# ATSAM4CMS16C_1 register map
Vendor: Atmel; Series: SAM4CM; File version: 0
CPU: CM4 r0p0, selectable endian, no MPU, FPU, 4 interrupt priority bits
Registers are 32-bit, read-write, reset 0x0 unless marked. A register's access mark holds for its fields unless they carry their own. Offsets are from the block's base; [hi:lo] are bit positions; {n}, {i} and the like mark numbered series; 'fields as' and 'values as' point back to an identical list.

## ADC — Analog-to-Digital Converter
Base 0x40038000; register names take the prefix ADC_
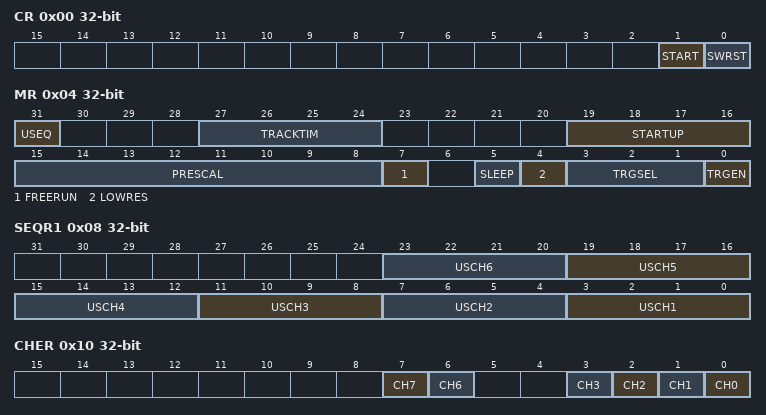
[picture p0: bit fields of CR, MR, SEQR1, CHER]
0x00 CR wo reset not defined — Control Register
  [1] START — Start Conversion
  [0] SWRST — Software Reset
0x04 MR — Mode Register
  [31] USEQ — User Sequence Enable
    0=NUM_ORDER (Normal Mode: The controller converts channels in a simple numeric order depending only on the channel index.); 1=REG_ORDER (User Sequence Mode: The sequence respects what is defined in ADC_SEQR1 and can be used to convert the same channel several times.)
  [27:24] TRACKTIM — Tracking Time
  [19:16] STARTUP — Start Up Time
    0=SUT0 (0 periods of ADC Clock); 1=SUT8 (8 periods of ADC Clock); 2=SUT16 (16 periods of ADC Clock); 3=SUT24 (24 periods of ADC Clock); 4=SUT64 (64 periods of ADC Clock); 5=SUT80 (80 periods of ADC Clock); 6=SUT96 (96 periods of ADC Clock); 7=SUT112 (112 periods of ADC Clock); 8=SUT512 (512 periods of ADC Clock); 9=SUT576 (576 periods of ADC Clock); 10=SUT640 (640 periods of ADC Clock); 11=SUT704 (704 periods of ADC Clock); 12=SUT768 (768 periods of ADC Clock); 13=SUT832 (832 periods of ADC Clock); 14=SUT896 (896 periods of ADC Clock); 15=SUT960 (960 periods of ADC Clock)
  [15:8] PRESCAL — Prescaler Rate Selection
  [7] FREERUN — Free Run Mode
    0=OFF (Normal Mode); 1=ON (Free Run Mode: Never wait for any trigger.)
  [5] SLEEP — Sleep Mode
    0=NORMAL (Normal Mode: The ADC core and reference voltage circuitry are kept ON between conversions); 1=SLEEP (Sleep Mode: The ADC core and reference voltage circuitry are OFF between conversions)
  [4] LOWRES — Resolution
    0=BITS_10 (10-bit resolution. For higher resolution by averaging, refer to Section 8.15 "ADC Extended Mode Register"); 1=BITS_8 (8-bit resolution)
  [3:1] TRGSEL — Trigger Selection
    0=ADC_TRIG0; {v}=ADC_TRIG{v} (Timer Counter Channel {v-1} Output) (v=1..6)
  [0] TRGEN — Trigger Enable
    0=DIS (Hardware triggers are disabled. Starting a conversion is only possible by software.); 1=EN (Hardware trigger selected by TRGSEL field is enabled.)
0x08 SEQR1 — Channel Sequence 1 Register
  [4n-1:4n-4] USCH{n} (n=1..6) — User Sequence Number {n}
0x10 CHER wo reset not defined — Channel Enable Register
  [7] CH7 — Channel 7 Enable
  [6] CH6 — Channel 6 Enable
  [n] CH{n} (n=0..3) — Channel {n} Enable
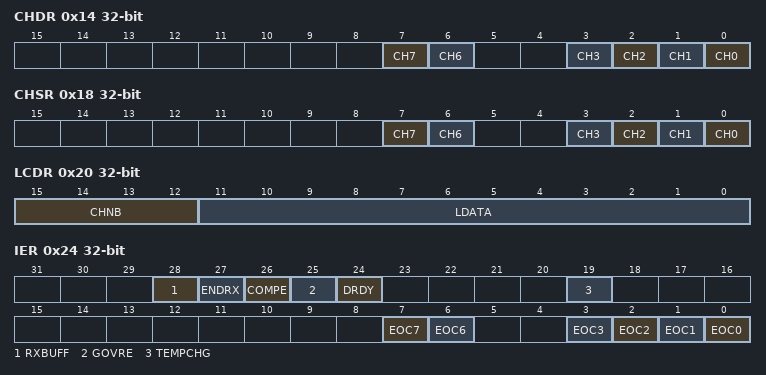
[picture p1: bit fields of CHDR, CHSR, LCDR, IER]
0x14 CHDR wo reset not defined — Channel Disable Register
  [7] CH7 — Channel 7 Disable
  [6] CH6 — Channel 6 Disable
  [n] CH{n} (n=0..3) — Channel {n} Disable
0x18 CHSR ro — Channel Status Register
  [7] CH7 — Channel 7 Status
  [6] CH6 — Channel 6 Status
  [n] CH{n} (n=0..3) — Channel {n} Status
0x20 LCDR ro — Last Converted Data Register
  [15:12] CHNB — Channel Number
  [11:0] LDATA — Last Data Converted
0x24 IER wo reset not defined — Interrupt Enable Register
  [28] RXBUFF — Receive Buffer Full Interrupt Enable
  [27] ENDRX — End of Receive Buffer Interrupt Enable
  [26] COMPE — Comparison Event Interrupt Enable
  [25] GOVRE — General Overrun Error Interrupt Enable
  [24] DRDY — Data Ready Interrupt Enable
  [19] TEMPCHG — Temperature Change Interrupt Enable
  [7] EOC7 — End of Conversion Interrupt Enable 7
  [6] EOC6 — End of Conversion Interrupt Enable 6
  [n] EOC{n} (n=0..3) — End of Conversion Interrupt Enable {n}
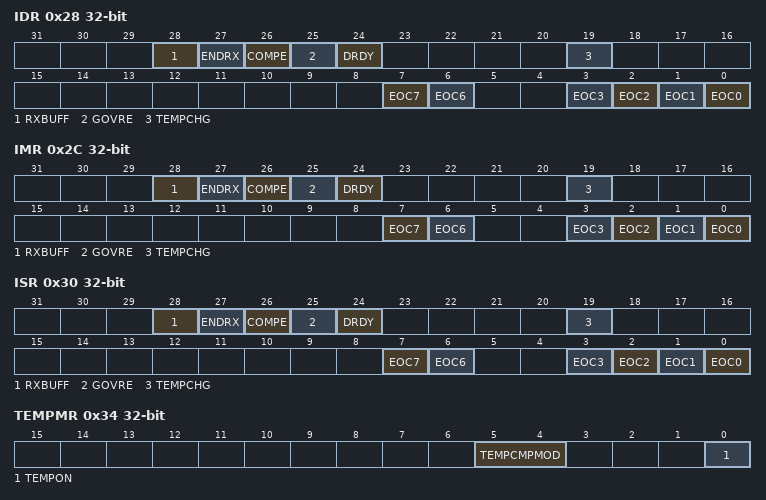
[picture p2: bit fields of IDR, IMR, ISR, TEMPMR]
0x28 IDR wo reset not defined — Interrupt Disable Register
  [28] RXBUFF — Receive Buffer Full Interrupt Disable
  [27] ENDRX — End of Receive Buffer Interrupt Disable
  [26] COMPE — Comparison Event Interrupt Disable
  [25] GOVRE — General Overrun Error Interrupt Disable
  [24] DRDY — Data Ready Interrupt Disable
  [19] TEMPCHG — Temperature Change Interrupt Disable
  [7] EOC7 — End of Conversion Interrupt Disable 7
  [6] EOC6 — End of Conversion Interrupt Disable 6
  [n] EOC{n} (n=0..3) — End of Conversion Interrupt Disable {n}
0x2C IMR ro — Interrupt Mask Register
  [28] RXBUFF — Receive Buffer Full Interrupt Mask
  [27] ENDRX — End of Receive Buffer Interrupt Mask
  [26] COMPE — Comparison Event Interrupt Mask
  [25] GOVRE — General Overrun Error Interrupt Mask
  [24] DRDY — Data Ready Interrupt Mask
  [19] TEMPCHG — Temperature Change Interrupt Mask
  [7] EOC7 — End of Conversion Interrupt Mask 7
  [6] EOC6 — End of Conversion Interrupt Mask 6
  [n] EOC{n} (n=0..3) — End of Conversion Interrupt Mask {n}
0x30 ISR ro — Interrupt Status Register
  [28] RXBUFF — Receive Buffer Full (automatically set/cleared)
  [27] ENDRX — End of Receive Transfer (automatically set/cleared)
  [26] COMPE — Comparison Event (cleared on read)
  [25] GOVRE — General Overrun Error (cleared on read)
  [24] DRDY — Data Ready (automatically set/cleared)
  [19] TEMPCHG — Temperature Change (cleared on read)
  [7] EOC7 — End of Conversion 7 (automatically set/cleared)
  [6] EOC6 — End of Conversion 6 (automatically set/cleared)
  [n] EOC{n} (n=0..3) — End of Conversion {n} (automatically set/cleared)
0x34 TEMPMR — Temperature Sensor Mode Register
  [5:4] TEMPCMPMOD — Temperature Comparison Mode
    0=LOW (Generates an event when the converted data is lower than the low threshold of the window.); 1=HIGH (Generates an event when the converted data is higher than the high threshold of the window.); 2=IN (Generates an event when the converted data is in the comparison window.); 3=OUT (Generates an event when the converted data is out of the comparison window.)
  [0] TEMPON — Temperature Sensor ON
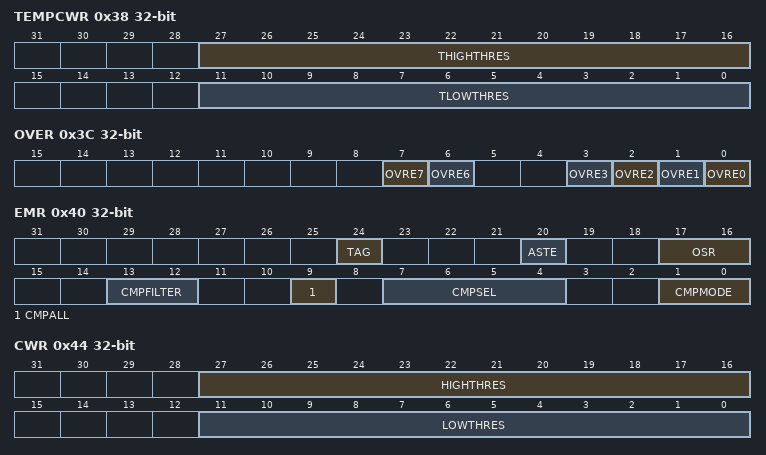
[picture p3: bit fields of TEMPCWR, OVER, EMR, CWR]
0x38 TEMPCWR — Temperature Compare Window Register
  [27:16] THIGHTHRES — Temperature High Threshold
  [11:0] TLOWTHRES — Temperature Low Threshold
0x3C OVER ro — Overrun Status Register
  [7] OVRE7 — Overrun Error 7
  [6] OVRE6 — Overrun Error 6
  [n] OVRE{n} (n=0..3) — Overrun Error {n}
0x40 EMR — Extended Mode Register
  [24] TAG — TAG of the ADC_LDCR register
  [20] ASTE — Averaging on Single Trigger Event
    0=MULTI_TRIG_AVERAGE (The average requests several trigger events.); 1=SINGLE_TRIG_AVERAGE (The average requests only one trigger event.)
  [17:16] OSR — Over Sampling Rate
    0=NO_AVERAGE (No averaging. ADC sample rate is maximum.); 1=1-bit enhanced resolution by averaging. ADC sample rate divided by 4.; 2=2-bit enhanced resolution by averaging. ADC sample rate divided by 16.
  [13:12] CMPFILTER — Compare Event Filtering
  [9] CMPALL — Compare All Channels
  [7:4] CMPSEL — Comparison Selected Channel
  [1:0] CMPMODE — Comparison Mode
    values as TEMPMR.TEMPCMPMOD
0x44 CWR — Compare Window Register
  [27:16] HIGHTHRES — High Threshold
  [11:0] LOWTHRES — Low Threshold
{0x50+4i} CDR[{i}] (i=0..7) ro reset not defined — Channel Data Register
  [11:0] DATA — Converted Data
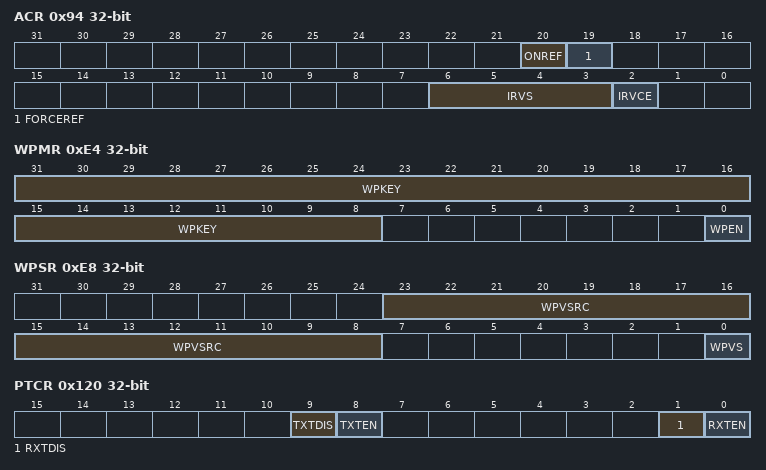
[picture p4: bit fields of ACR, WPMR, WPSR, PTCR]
0x94 ACR — Analog Control Register
  [20] ONREF — Internal Voltage Reference ON
  [19] FORCEREF — Force Internal Reference Voltage
  [6:3] IRVS — Internal Reference Voltage Selection
  [2] IRVCE — Internal Reference Voltage Change Enable
    0=STUCK_AT_DEFAULT (The internal reference voltage is stuck at the default value (see the Electrical Characteristics for further details).); 1=SELECTION (The internal reference voltage is defined by field IRVS.)
0xE4 WPMR — Write Protection Mode Register
  [31:8] WPKEY — Write Protect Key
    0x414443=PASSWD (Writing any other value in this field aborts the write operation of the WPEN bit.Always reads as 0)
  [0] WPEN — Write Protect Enable
0xE8 WPSR ro — Write Protection Status Register
  [23:8] WPVSRC — Write Protection Violation Source
  [0] WPVS — Write Protection Violation Status
0x100 RPR — Receive Pointer Register
  [31:0] RXPTR
0x104 RCR — Receive Counter Register
  [15:0] RXCTR
0x110 RNPR — Receive Next Pointer Register
  [31:0] RXNPTR — Receive Next Pointer
0x114 RNCR — Receive Next Counter Register
  [15:0] RXNCTR — Receive Next Counter
0x120 PTCR wo — Transfer Control Register
  [9] TXTDIS — Transmitter Transfer Disable
  [8] TXTEN — Transmitter Transfer Enable
  [1] RXTDIS — Receiver Transfer Disable
  [0] RXTEN — Receiver Transfer Enable
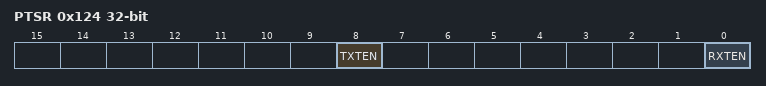
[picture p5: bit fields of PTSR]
0x124 PTSR ro — Transfer Status Register
  [8] TXTEN — Transmitter Transfer Enable
  [0] RXTEN — Receiver Transfer Enable

## Notices in the file
SAM Software Package License
Copyright (c) 2015, Atmel Corporation
All rights reserved.
Redistribution and use in source and binary forms, with or without
modification, are permitted provided that the following condition is met:
- Redistributions of source code must retain the above copyright notice,
this list of conditions and the disclaimer below.
Atmel's name may not be used to endorse or promote products derived from
this software without specific prior written permission.
DISCLAIMER:  THIS SOFTWARE IS PROVIDED BY ATMEL "AS IS" AND ANY EXPRESS OR
IMPLIED WARRANTIES, INCLUDING, BUT NOT LIMITED TO, THE IMPLIED WARRANTIES OF
MERCHANTABILITY, FITNESS FOR A PARTICULAR PURPOSE AND NON-INFRINGEMENT ARE
DISCLAIMED. IN NO EVENT SHALL ATMEL BE LIABLE FOR ANY DIRECT, INDIRECT,
INCIDENTAL, SPECIAL, EXEMPLARY, OR CONSEQUENTIAL DAMAGES (INCLUDING, BUT NOT
LIMITED TO, PROCUREMENT OF SUBSTITUTE GOODS OR SERVICES; LOSS OF USE, DATA,
OR PROFITS; OR BUSINESS INTERRUPTION) HOWEVER CAUSED AND ON ANY THEORY OF
LIABILITY, WHETHER IN CONTRACT, STRICT LIABILITY, OR TORT (INCLUDING
NEGLIGENCE OR OTHERWISE) ARISING IN ANY WAY OUT OF THE USE OF THIS SOFTWARE,
EVEN IF ADVISED OF THE POSSIBILITY OF SUCH DAMAGE.
